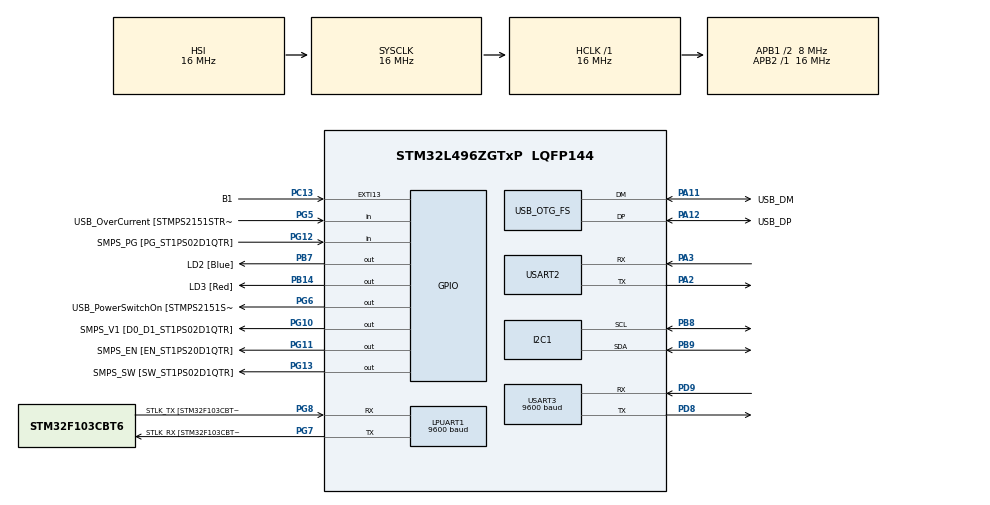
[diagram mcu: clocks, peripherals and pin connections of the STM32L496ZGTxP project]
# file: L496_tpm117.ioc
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Dma.Request0=USART3_TX
Dma.USART3_TX.0.Direction=DMA_MEMORY_TO_PERIPH
Dma.USART3_TX.0.Instance=DMA1_Channel2
Dma.USART3_TX.0.MemDataAlignment=DMA_MDATAALIGN_BYTE
Dma.USART3_TX.0.MemInc=DMA_MINC_ENABLE
Dma.USART3_TX.0.Mode=DMA_NORMAL
Dma.USART3_TX.0.PeriphDataAlignment=DMA_PDATAALIGN_BYTE
Dma.USART3_TX.0.PeriphInc=DMA_PINC_DISABLE
Dma.USART3_TX.0.Priority=DMA_PRIORITY_LOW
I2C1.Timing=0x2000090E
LPUART1.BaudRate=9600
LPUART1.WordLength=UART_WORDLENGTH_8B
Mcu.Family=STM32L4
Mcu.Name=STM32L496ZGTxP
Mcu.Package=LQFP144
NVIC.DMA1_Channel2_IRQn=true\:0\:0\:false\:false\:true\:false\:true\:true
NVIC.LPUART1_IRQn=true\:0\:0\:false\:false\:true\:true\:true\:true
NVIC.OTG_FS_IRQn=true\:0\:0\:false\:false\:true\:true\:true\:true
NVIC.PriorityGroup=NVIC_PRIORITYGROUP_4
NVIC.USART3_IRQn=true\:0\:0\:false\:false\:true\:true\:true\:true
PA10.GPIO_Label=USB_ID
PA10.Signal=USB_OTG_FS_ID
PA11.GPIO_Label=USB_DM
PA11.Mode=Host_Only
PA11.Signal=USB_OTG_FS_DM
PA12.GPIO_Label=USB_DP
PA12.Mode=Host_Only
PA12.Signal=USB_OTG_FS_DP
PA13\ (JTMS/SWDIO).GPIO_Label=TMS
PA13\ (JTMS/SWDIO).Mode=Trace_Asynchronous_SW
PA13\ (JTMS/SWDIO).Signal=SYS_JTMS-SWDIO
PA14\ (JTCK/SWCLK).GPIO_Label=TCK
PA14\ (JTCK/SWCLK).Mode=Trace_Asynchronous_SW
PA14\ (JTCK/SWCLK).Signal=SYS_JTCK-SWCLK
PA2.Mode=Asynchronous
PA2.Signal=USART2_TX
PA3.Mode=Asynchronous
PA3.Signal=USART2_RX
PA8.GPIO_Label=USB_SOF [TP1]
PA8.Signal=USB_OTG_FS_SOF
PA9.GPIO_Label=USB_VBUS
PA9.Signal=USB_OTG_FS_VBUS
PB14.GPIO_Label=LD3 [Red]
PB14.Signal=GPIO_Output
PB3\ (JTDO/TRACESWO).GPIO_Label=SWO
PB3\ (JTDO/TRACESWO).Mode=Trace_Asynchronous_SW
PB3\ (JTDO/TRACESWO).Signal=SYS_JTDO-SWO
PB7.GPIO_Label=LD2 [Blue]
PB7.Signal=GPIO_Output
PB8.Mode=I2C
PB8.Signal=I2C1_SCL
PB9.Mode=I2C
PB9.Signal=I2C1_SDA
PC13.GPIO_Label=B1
PC13.Signal=GPXTI13
PC14-OSC32_IN\ (PC14).Mode=LSE-External-Oscillator
PC14-OSC32_IN\ (PC14).Signal=RCC_OSC32_IN
PC15-OSC32_OUT\ (PC15).Mode=LSE-External-Oscillator
PC15-OSC32_OUT\ (PC15).Signal=RCC_OSC32_OUT
PD8.Mode=Asynchronous
PD8.Signal=USART3_TX
PD9.Mode=Asynchronous
PD9.Signal=USART3_RX
PG10.GPIO_Label=SMPS_V1 [D0_D1_ST1PS02D1QTR]
PG10.Signal=GPIO_Output
PG11.GPIO_Label=SMPS_EN [EN_ST1PS20D1QTR]
PG11.Signal=GPIO_Output
PG12.GPIO_Label=SMPS_PG [PG_ST1PS02D1QTR]
PG12.Signal=GPIO_Input
PG13.GPIO_Label=SMPS_SW [SW_ST1PS02D1QTR]
PG13.Signal=GPIO_Output
PG5.GPIO_Label=USB_OverCurrent [STMPS2151STR_FAULT]
PG5.Signal=GPIO_Input
PG6.GPIO_Label=USB_PowerSwitchOn [STMPS2151STR_EN]
PG6.Signal=GPIO_Output
PG7.GPIO_Label=STLK_RX [STM32F103CBT6_PA3]
PG7.Mode=Asynchronous
PG7.Signal=LPUART1_TX
PG8.GPIO_Label=STLK_TX [STM32F103CBT6_PA2]
PG8.Mode=Asynchronous
PG8.Signal=LPUART1_RX
PH0-OSC_IN\ (PH0).GPIO_Label=MCO
PH0-OSC_IN\ (PH0).Mode=HSE-External-Oscillator
PH0-OSC_IN\ (PH0).Signal=RCC_OSC_IN
PH1-OSC_OUT\ (PH1).Mode=HSE-External-Oscillator
PH1-OSC_OUT\ (PH1).Signal=RCC_OSC_OUT
ProjectManager.HeapSize=0x200
ProjectManager.StackSize=0x400
ProjectManager.TargetToolchain=STM32CubeIDE
RCC.48MHZClocksFreq_Value=24000000
RCC.ADCFreq_Value=48000000
RCC.AHBFreq_Value=16000000
RCC.APB1CLKDivider=RCC_HCLK_DIV2
RCC.APB1Freq_Value=8000000
RCC.APB1TimFreq_Value=16000000
RCC.APB2Freq_Value=16000000
RCC.APB2TimFreq_Value=16000000
RCC.CortexFreq_Value=16000000
RCC.HCLKFreq_Value=16000000
RCC.HSE_VALUE=8000000
RCC.HSI48_VALUE=48000000
RCC.HSI_VALUE=16000000
RCC.MSIClockRange=RCC_MSIRANGE_9
RCC.MSI_VALUE=24000000
RCC.PLLM=5
RCC.PLLMUL=RCC_PLL_MUL9
RCC.PLLN=71
RCC.PLLR=RCC_PLLR_DIV6
RCC.PLLSAI1N=20
RCC.PRESCALERUSB=RCC_USBCLKSOURCE_PLL_DIV1_5
RCC.SYSCLKFreq_VALUE=16000000
RCC.SYSCLKSource=RCC_SYSCLKSOURCE_HSI
RCC.SYSCLKSourceVirtual=RCC_SYSCLKSOURCE_PLLCLK
RCC.USBFreq_Value=48000000
RCC.VCOOutputFreq_Value=340800000
USART2.VirtualMode-Asynchronous=VM_ASYNC
USART3.BaudRate=9600
USART3.VirtualMode-Asynchronous=VM_ASYNC
USB_HOST.BSP.number=1
USB_HOST.USBH_HandleTypeDef=hUsbHostFS
USB_HOST.VirtualModeFS=Audio
USB_HOST0.BSP.STBoard=false
USB_HOST0.BSP.api=UnknownBspDriver
USB_HOST0.BSP.instance=PG6
USB_HOST0.BSP.ip=GPIO
USB_HOST0.BSP.mode=Output
USB_HOST0.BSP.name=Drive_VBUS_FS
USB_HOST0.BSP.solution=PG6
USB_OTG_FS.VirtualMode=Host_Only
USB_OTG_FS.phy_itface=HCD_PHY_EMBEDDED
VP_USB_HOST_VS_USB_HOST_AUDIO_FS.Mode=AUDIO_FS
board=NUCLEO-L496ZG-P

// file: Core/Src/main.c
/* USER CODE BEGIN Header */
/**
  ******************************************************************************
  * @file           : main.c
  * @brief          : Main program body
  ******************************************************************************
  * @attention
  *
  * Copyright (c) 2023 STMicroelectronics.
  * All rights reserved.
  *
  * This software is licensed under terms that can be found in the LICENSE file
  * in the root directory of this software component.
  * If no LICENSE file comes with this software, it is provided AS-IS.
  *
  ******************************************************************************
  */
/* USER CODE END Header */
#include "main.h"
#include "dma.h"
#include "i2c.h"
#include "usart.h"
#include "usb_host.h"
#include "gpio.h"

/* USER CODE BEGIN Includes */
#include <stdio.h>
#include <string.h>
/* USER CODE END Includes */

void SystemClock_Config(void);
void MX_USB_HOST_Process(void);

/* USER CODE BEGIN PFP */
/*
int _write(int file, char *ptr, int len)
{
	HAL_UART_Transmit(&hlpuart1, (uint8_t*)ptr, len, HAL_MAX_DELAY);
	return len;
}
*/
/* USER CODE END PFP */

/* USER CODE BEGIN 0 */
uint8_t data[] = "12345678910 \r\n";

/* USER CODE END 0 */

int main(void)
{
  /* USER CODE BEGIN 1 */
   //uint8_t buf[12];
	//uint8_t msg[30]={'\0'};
	//uint8_t a=0;

  /* USER CODE END 1 */

  /* MCU Configuration--------------------------------------------------------*/

  /* Reset of all peripherals, Initializes the Flash interface and the Systick. */
  HAL_Init();

  /* USER CODE BEGIN Init */
  uint8_t Rx_data[10];  //  creating a buffer of 10 bytes

  /* USER CODE END Init */

  /* Configure the system clock */
  SystemClock_Config();

  /* Initialize all configured peripherals */
  MX_GPIO_Init();
  MX_DMA_Init();
  MX_LPUART1_UART_Init();
  MX_USB_HOST_Init();
  MX_USART3_UART_Init();
  MX_I2C1_Init();
  MX_USART2_UART_Init();

  /* Infinite loop */
  /* USER CODE BEGIN WHILE */
 while (1)
  {

	//  strcpy((char*)buf,"Hello\r\n");
	  //HAL_UART_Transmit(&hlpuart1,buf,strlen((char*)buf),HAL_MAX_DELAY);
	  	//  HAL_Delay(1000);

	 /* strcpy((char*)msg,"hello\r\n");
	  		 HAL_UART_Transmit(&hlpuart1,msg,strlen((char*)msg),HAL_MAX_DELAY);
	  		  HAL_Delay(1000);   */

	  	 /* sprintf(msg,"hello a=%d\r\n",a);
	 	  HAL_UART_Transmit(&hlpuart1,msg,sizeof(msg),100);
	 	  HAL_Delay(500);
	 	  a++;
	 	   */

	  //  printf("output\r\n");
	  // HAL_UART_Transmit(&huart3,buf,strlen((char*)buf),HAL_MAX_DELAY);     // for sending our message;

    /* USER CODE END WHILE */
    MX_USB_HOST_Process();

    /* USER CODE BEGIN 3 */
   // HAL_UART_Receive (&huart3, Rx_data, 4, 100);
    HAL_GPIO_TogglePin (GPIOB,GPIO_PIN_7);

    HAL_Delay (250);  // 250 ms delay

    HAL_UART_Transmit (&huart3, data, sizeof (data), 10);

    //HAL_UART_Transmit (&huart3, Rx_data, 4, 100);//

    HAL_UART_Transmit (&hlpuart1, data, sizeof (data), 10);

  }
  /* USER CODE END 3 */
}

void SystemClock_Config(void)
{
  RCC_OscInitTypeDef RCC_OscInitStruct = {0};
  RCC_ClkInitTypeDef RCC_ClkInitStruct = {0};

  /** Configure the main internal regulator output voltage
  */
  if (HAL_PWREx_ControlVoltageScaling(PWR_REGULATOR_VOLTAGE_SCALE1) != HAL_OK)
  {
    Error_Handler();
  }

  /** Configure LSE Drive Capability
  */
  HAL_PWR_EnableBkUpAccess();
  __HAL_RCC_LSEDRIVE_CONFIG(RCC_LSEDRIVE_LOW);

  /** Initializes the RCC Oscillators according to the specified parameters
  * in the RCC_OscInitTypeDef structure.
  */
  RCC_OscInitStruct.OscillatorType = RCC_OSCILLATORTYPE_HSI|RCC_OSCILLATORTYPE_LSE
                              |RCC_OSCILLATORTYPE_MSI;
  RCC_OscInitStruct.LSEState = RCC_LSE_ON;
  RCC_OscInitStruct.HSIState = RCC_HSI_ON;
  RCC_OscInitStruct.HSICalibrationValue = RCC_HSICALIBRATION_DEFAULT;
  RCC_OscInitStruct.MSIState = RCC_MSI_ON;
  RCC_OscInitStruct.MSICalibrationValue = 0;
  RCC_OscInitStruct.MSIClockRange = RCC_MSIRANGE_9;
  RCC_OscInitStruct.PLL.PLLState = RCC_PLL_NONE;
  if (HAL_RCC_OscConfig(&RCC_OscInitStruct) != HAL_OK)
  {
    Error_Handler();
  }

  /** Initializes the CPU, AHB and APB buses clocks
  */
  RCC_ClkInitStruct.ClockType = RCC_CLOCKTYPE_HCLK|RCC_CLOCKTYPE_SYSCLK
                              |RCC_CLOCKTYPE_PCLK1|RCC_CLOCKTYPE_PCLK2;
  RCC_ClkInitStruct.SYSCLKSource = RCC_SYSCLKSOURCE_HSI;
  RCC_ClkInitStruct.AHBCLKDivider = RCC_SYSCLK_DIV1;
  RCC_ClkInitStruct.APB1CLKDivider = RCC_HCLK_DIV2;
  RCC_ClkInitStruct.APB2CLKDivider = RCC_HCLK_DIV1;

  if (HAL_RCC_ClockConfig(&RCC_ClkInitStruct, FLASH_LATENCY_0) != HAL_OK)
  {
    Error_Handler();
  }

  /** Enable MSI Auto calibration
  */
  HAL_RCCEx_EnableMSIPLLMode();
}

void Error_Handler(void)
{
  __disable_irq();
  while (1)
  {
  }
}
